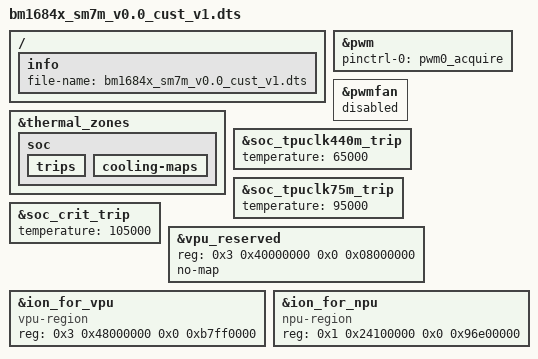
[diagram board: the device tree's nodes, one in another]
#include "bm1684x.dtsi"
#include "bm1684x_mm_16g.dtsi"
#include "bm1684x_evb.dtsi"

/ {
	/delete-node/ pka@58008000;
	/delete-node/ clp890@50018000;
	info {
		file-name = "bm1684x_sm7m_v0.0_cust_v1.dts";
	};
};

&pwm{
	pinctrl-names = "default";
	pinctrl-0 = <&pwm0_acquire>;
};

&pwmfan {
	status = "disabled";
};

&thermal_zones {
	soc {
		trips {
			/delete-node/ soc_pwmfan_trip@0;
			/delete-node/ soc_pwmfan_trip@1;
			/delete-node/ soc_pwmfan_trip@2;
			/delete-node/ soc_pwmfan_trip@3;
			/delete-node/ soc_pwmfan_trip@4;
		};

		cooling-maps {
			/delete-node/ map3;
			/delete-node/ map4;
			/delete-node/ map5;
			/delete-node/ map6;
			/delete-node/ map7;
		};
	};
};

&soc_tpuclk440m_trip {
	temperature = <65000>;
};

&soc_tpuclk75m_trip {
	temperature = <95000>;
};

&soc_crit_trip {
	temperature = <105000>;
};

&vpu_reserved {
	reg = <0x3 0x40000000 0x0 0x08000000>; // 128M, for VPU firmware
	no-map;
};

&ion_for_vpu {
			compatible = "vpu-region";
			reg = <0x3 0x48000000 0x0 0xb7ff0000>; // 2.875G
};

&ion_for_npu {
			compatible = "npu-region";
			reg = <0x1 0x24100000 0x0 0x96e00000>; // 2.5g
};
